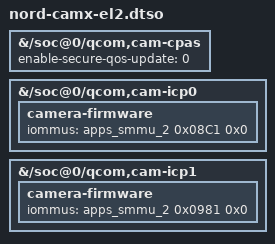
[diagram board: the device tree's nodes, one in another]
// SPDX-License-Identifier: BSD-3-Clause
/*
 * Copyright (c) Qualcomm Technologies, Inc. and/or its subsidiaries.
 */

/dts-v1/;
/plugin/;

/ {
	fragment@0 {
		target-path = "/soc@0/qcom,cam-cpas";
		__overlay__ {
			enable-secure-qos-update = <0>;
		};
	};

	fragment@1 {
		target-path = "/soc@0/qcom,cam-icp0";
		__overlay__ {
			camera-firmware {
				iommus = <&apps_smmu_2 0x08C1 0x0>;
			};
		};
	};

	fragment@2 {
		target-path = "/soc@0/qcom,cam-icp1";
		__overlay__ {
			camera-firmware {
				iommus = <&apps_smmu_2 0x0981 0x0>;
			};
		};
	};
};
